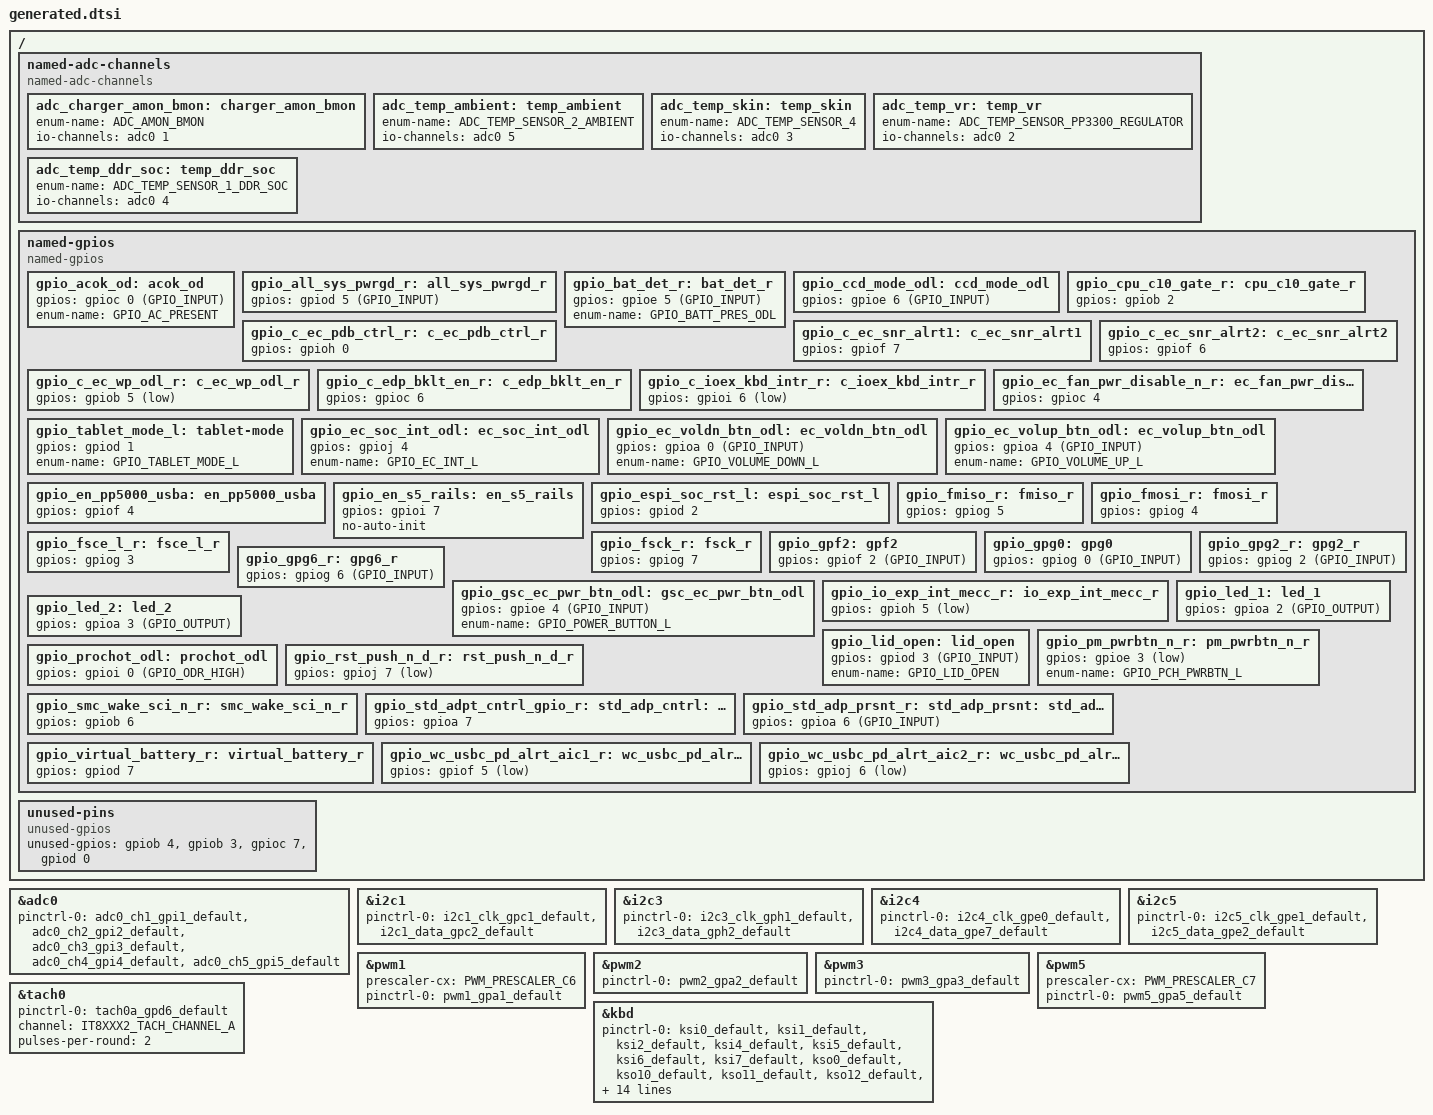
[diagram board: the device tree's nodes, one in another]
/* Copyright 2025 The ChromiumOS Authors
 * Use of this source code is governed by a BSD-style license that can be
 * found in the LICENSE file.
 *
 * This file was auto-generated but contains manual edits
 */

/ {

	named-adc-channels {
		compatible = "named-adc-channels";

		adc_charger_amon_bmon: charger_amon_bmon {
			enum-name = "ADC_AMON_BMON";
			io-channels = <&adc0 1>;
		};
		adc_temp_ambient: temp_ambient {
			enum-name = "ADC_TEMP_SENSOR_2_AMBIENT";
			io-channels = <&adc0 5>;
		};
		adc_temp_skin: temp_skin {
			enum-name = "ADC_TEMP_SENSOR_4";
			io-channels = <&adc0 3>;
		};
		adc_temp_vr: temp_vr {
			enum-name = "ADC_TEMP_SENSOR_PP3300_REGULATOR";
			io-channels = <&adc0 2>;
		};
		adc_temp_ddr_soc: temp_ddr_soc {
			enum-name = "ADC_TEMP_SENSOR_1_DDR_SOC";
			io-channels = <&adc0 4>;
		};
	};

	named-gpios {
		compatible = "named-gpios";

		gpio_acok_od: acok_od {
			// signal name was manually overriden from "bga_pine5"
			gpios = <&gpioc 0 (GPIO_INPUT)>;
			enum-name = "GPIO_AC_PRESENT";
		};
		gpio_all_sys_pwrgd_r: all_sys_pwrgd_r {
			gpios = <&gpiod 5 (GPIO_INPUT)>;
		};
		gpio_bat_det_r: bat_det_r {
			gpios = <&gpioe 5 (GPIO_INPUT)>;
			enum-name = "GPIO_BATT_PRES_ODL";
		};
		gpio_ccd_mode_odl: ccd_mode_odl {
			// signal name was manually overriden from "bga_pinm1"
			gpios = <&gpioe 6 (GPIO_INPUT)>;
		};
		gpio_cpu_c10_gate_r: cpu_c10_gate_r {
			gpios = <&gpiob 2 (GPIO_INPUT | GPIO_VOLTAGE_1P8)>;
		};
		gpio_c_ec_pdb_ctrl_r: c_ec_pdb_ctrl_r {
			gpios = <&gpioh 0 (GPIO_OUTPUT | GPIO_ACTIVE_HIGH | GPIO_OUTPUT_INIT_HIGH |
						GPIO_OUTPUT_INIT_LOGICAL)>;
		};
		gpio_c_ec_snr_alrt1: c_ec_snr_alrt1 {
			// signal name was manually overriden from "bga_pinc1"
			gpios = <&gpiof 7 (GPIO_INPUT | GPIO_VOLTAGE_1P8)>;
		};
		gpio_c_ec_snr_alrt2: c_ec_snr_alrt2 {
			// signal name was manually overriden from "bga_pinb1"
			gpios = <&gpiof 6 (GPIO_INPUT | GPIO_VOLTAGE_1P8)>;
		};
		gpio_c_ec_wp_odl_r: c_ec_wp_odl_r {
			gpios = <&gpiob 5 (GPIO_INPUT | GPIO_ACTIVE_LOW)>;
		};
		gpio_c_edp_bklt_en_r: c_edp_bklt_en_r {
			gpios = <&gpioc 6 (GPIO_OUTPUT | GPIO_ACTIVE_HIGH | GPIO_OUTPUT_INIT_HIGH |
						GPIO_OUTPUT_INIT_LOGICAL)>;
		};
		gpio_c_ioex_kbd_intr_r: c_ioex_kbd_intr_r {
			gpios = <&gpioi 6 (GPIO_INPUT | GPIO_ACTIVE_LOW)>;
		};
		gpio_ec_fan_pwr_disable_n_r: ec_fan_pwr_disable_n_r {
			gpios = <&gpioc 4 (GPIO_OUTPUT | GPIO_ACTIVE_HIGH | GPIO_OUTPUT_INIT_LOW)>;
		};
		gpio_tablet_mode_l: tablet-mode {
			gpios = <&gpiod 1 (GPIO_INPUT | GPIO_VOLTAGE_1P8)>;
			enum-name = "GPIO_TABLET_MODE_L";
		};
		gpio_ec_soc_int_odl: ec_soc_int_odl {
			gpios = <&gpioj 4 (GPIO_OUTPUT | GPIO_OPEN_DRAIN | GPIO_ACTIVE_HIGH | GPIO_OUTPUT_INIT_HIGH)>;
			enum-name = "GPIO_EC_INT_L";
		};
		gpio_ec_voldn_btn_odl: ec_voldn_btn_odl {
			// signal name was manually overriden from "vol_dn_ec_r"
			gpios = <&gpioa 0 (GPIO_INPUT)>;
			enum-name = "GPIO_VOLUME_DOWN_L";
		};
		gpio_ec_volup_btn_odl: ec_volup_btn_odl {
			// signal name was manually overriden from "volume_up_r"
			gpios = <&gpioa 4 (GPIO_INPUT)>;
			enum-name = "GPIO_VOLUME_UP_L";
		};
		gpio_en_pp5000_usba: en_pp5000_usba {
			// signal name was manually overriden from "c_en_pp5000_typea_r"
			gpios = <&gpiof 4 (GPIO_OUTPUT | GPIO_ACTIVE_HIGH)>;
		};
		/* Power sequencing signal needed by temp sensor driver */
		gpio_en_s5_rails: en_s5_rails {
			gpios = <&gpioi 7 (GPIO_OUTPUT | GPIO_ACTIVE_HIGH | GPIO_OUTPUT_INIT_LOW)>;
			no-auto-init;
		};
		gpio_espi_soc_rst_l: espi_soc_rst_l {
			gpios = <&gpiod 2 (GPIO_INPUT | GPIO_VOLTAGE_1P8)>;
		};
		gpio_fmiso_r: fmiso_r {
			gpios = <&gpiog 5 (GPIO_INPUT | GPIO_PULL_UP)>;
		};
		gpio_fmosi_r: fmosi_r {
			gpios = <&gpiog 4 (GPIO_INPUT | GPIO_PULL_DOWN)>;
		};
		gpio_fsce_l_r: fsce_l_r {
			gpios = <&gpiog 3 (GPIO_INPUT | GPIO_PULL_UP)>;
		};
		gpio_fsck_r: fsck_r {
			gpios = <&gpiog 7 (GPIO_INPUT | GPIO_PULL_DOWN)>;
		};
		gpio_gpf2: gpf2 {
			// signal name was manually overriden from "bga_pina10"
			gpios = <&gpiof 2 (GPIO_INPUT)>;
		};
		gpio_gpg0: gpg0 {
			gpios = <&gpiog 0 (GPIO_INPUT)>;
		};
		gpio_gpg2_r: gpg2_r {
			gpios = <&gpiog 2 (GPIO_INPUT)>;
		};
		gpio_gpg6_r: gpg6_r {
			gpios = <&gpiog 6 (GPIO_INPUT)>;
		};
		gpio_gsc_ec_pwr_btn_odl: gsc_ec_pwr_btn_odl {
			// signal name was manually overriden from "bga_pinb4"
			gpios = <&gpioe 4 (GPIO_INPUT)>;
			enum-name = "GPIO_POWER_BUTTON_L";
		};
		gpio_io_exp_int_mecc_r: io_exp_int_mecc_r {
			gpios = <&gpioh 5 (GPIO_INPUT | GPIO_ACTIVE_LOW)>;
		};
		gpio_led_1: led_1 {
			gpios = <&gpioa 2 (GPIO_OUTPUT)>;
		};
		gpio_led_2: led_2 {
			gpios = <&gpioa 3 (GPIO_OUTPUT)>;
		};
		gpio_lid_open: lid_open {
			gpios = <&gpiod 3 (GPIO_INPUT)>;
			enum-name = "GPIO_LID_OPEN";
		};
		gpio_pm_pwrbtn_n_r: pm_pwrbtn_n_r {
			gpios = <&gpioe 3 (GPIO_OUTPUT | GPIO_OPEN_DRAIN | GPIO_ACTIVE_LOW)>;
			enum-name = "GPIO_PCH_PWRBTN_L";
		};
		gpio_prochot_odl: prochot_odl {
			gpios = <&gpioi 0 (GPIO_ODR_HIGH)>;
		};
		gpio_rst_push_n_d_r: rst_push_n_d_r {
			gpios = <&gpioj 7 (GPIO_OUTPUT | GPIO_OPEN_DRAIN | GPIO_ACTIVE_LOW | GPIO_OUTPUT_INIT_HIGH)>;
		};
		gpio_smc_wake_sci_n_r: smc_wake_sci_n_r {
			gpios = <&gpiob 6 (GPIO_OUTPUT | GPIO_OPEN_DRAIN | GPIO_ACTIVE_HIGH | GPIO_OUTPUT_INIT_HIGH)>;
		};
		gpio_std_adpt_cntrl_gpio_r: std_adp_cntrl: std_adpt_cntrl_gpio_r {
			gpios = <&gpioa 7 (GPIO_OUTPUT | GPIO_ACTIVE_HIGH)>;
		};
		gpio_std_adp_prsnt_r: std_adp_prsnt: std_adp_prsnt_r {
			gpios = <&gpioa 6 (GPIO_INPUT)>;
		};
		gpio_virtual_battery_r: virtual_battery_r {
			gpios = <&gpiod 7 (GPIO_INPUT | GPIO_PULL_UP)>;
		};
		gpio_wc_usbc_pd_alrt_aic1_r: wc_usbc_pd_alrt_aic1_r {
			gpios = <&gpiof 5 (GPIO_INPUT | GPIO_ACTIVE_LOW)>;
		};
		gpio_wc_usbc_pd_alrt_aic2_r: wc_usbc_pd_alrt_aic2_r {
			gpios = <&gpioj 6 (GPIO_INPUT | GPIO_ACTIVE_LOW)>;
		};
	};

	unused-pins {
		compatible = "unused-gpios";
		unused-gpios =
			/* BGA_PINA2 - unused 1.8V I2C bus - pull down to avoid
			 * voltage level issues if this AIC is connected to a
			 * different base RVP board */
			<&gpiob 4 (GPIO_INPUT | GPIO_PULL_DOWN)>,
			/* BGA_PINA5 - unused 1.8V I2C bus - pull down to avoid
			 * voltage level issues if this AIC is connected to a
			 * different base RVP board */
			<&gpiob 3 (GPIO_INPUT | GPIO_PULL_DOWN)>,
			/* BGA_PINM2 */
			<&gpioc 7 (GPIO_INPUT | GPIO_PULL_UP)>,
			/* BGA_PINN1 */
			<&gpiod 0 (GPIO_INPUT | GPIO_PULL_UP)>;
	};
};

&adc0 {
	status = "okay";
	pinctrl-0 = <&adc0_ch1_gpi1_default
		&adc0_ch2_gpi2_default
		&adc0_ch3_gpi3_default
		&adc0_ch4_gpi4_default
		&adc0_ch5_gpi5_default>;
	pinctrl-names = "default";
};

&i2c1 {
	status = "okay";
	pinctrl-0 = <&i2c1_clk_gpc1_default
		&i2c1_data_gpc2_default>;
	pinctrl-names = "default";
};

&i2c3 {
	status = "okay";
	pinctrl-0 = <&i2c3_clk_gph1_default
		&i2c3_data_gph2_default>;
	pinctrl-names = "default";
};

&i2c4 {
	status = "okay";
	pinctrl-0 = <&i2c4_clk_gpe0_default
		&i2c4_data_gpe7_default>;
	pinctrl-names = "default";
};

&i2c5 {
	status = "okay";
	pinctrl-0 = <&i2c5_clk_gpe1_default
		&i2c5_data_gpe2_default>;
	pinctrl-names = "default";
};

&pwm1 {
	status = "okay";
	prescaler-cx = <PWM_PRESCALER_C6>;
	pinctrl-0 = <&pwm1_gpa1_default>;
	pinctrl-names = "default";
};

&pwm2 {
	status = "okay";
	pinctrl-0 = <&pwm2_gpa2_default>;
	pinctrl-names = "default";
};

&pwm3 {
	status = "okay";
	pinctrl-0 = <&pwm3_gpa3_default>;
	pinctrl-names = "default";
};

&pwm5 {
	status = "okay";
	prescaler-cx = <PWM_PRESCALER_C7>;
	pinctrl-0 = <&pwm5_gpa5_default>;
	pinctrl-names = "default";
};

&tach0 {
	status = "okay";
	pinctrl-0 = <&tach0a_gpd6_default>;
	pinctrl-names = "default";
	channel = <IT8XXX2_TACH_CHANNEL_A>;
	pulses-per-round = <2>;
};

&kbd {
	status = "okay";
	pinctrl-0 = <
		&ksi0_default
		&ksi1_default
		&ksi2_default
		&ksi4_default
		&ksi5_default
		&ksi6_default
		&ksi7_default
		&kso0_default
		&kso10_default
		&kso11_default
		&kso12_default
		&kso13_default
		&kso14_default
		&kso15_default
		&kso16_default
		&kso17_default
		&kso1_default
		&kso2_default
		&kso3_default
		&kso4_default
		&kso5_default
		&kso6_default
		&kso7_default
		&kso8_default
		&kso9_default
	>;
	pinctrl-1 = <
		&ksi0_sleep
		&ksi1_sleep
		&ksi2_sleep
		&ksi4_sleep
		&ksi5_sleep
		&ksi6_sleep
		&ksi7_sleep
		&kso0_sleep
		&kso10_sleep
		&kso11_sleep
		&kso12_sleep
		&kso13_sleep
		&kso14_sleep
		&kso15_sleep
		&kso16_sleep
		&kso17_sleep
		&kso1_sleep
		&kso2_sleep
		&kso3_sleep
		&kso4_sleep
		&kso5_sleep
		&kso6_sleep
		&kso7_sleep
		&kso8_sleep
		&kso9_sleep
	>;
	pinctrl-names = "default", "sleep";
};
